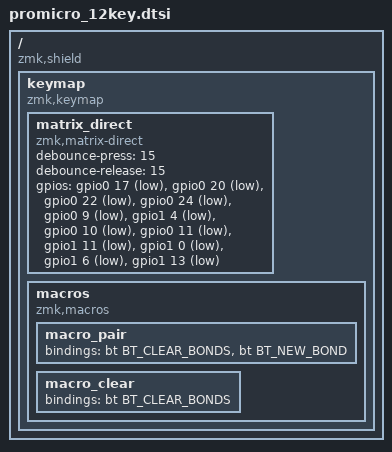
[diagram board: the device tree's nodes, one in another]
/ {
    compatible = "zmk,shield";

    keymap {
        compatible = "zmk,keymap";

        matrix_direct {
            compatible = "zmk,matrix-direct";
            //导电胶消抖15ms
            debounce-press = <15>;
            debounce-release = <15>;

            gpios =
                <&gpio0 17 GPIO_ACTIVE_LOW>,  // W
                <&gpio0 20 GPIO_ACTIVE_LOW>,  // A
                <&gpio0 22 GPIO_ACTIVE_LOW>,  // S
                <&gpio0 24 GPIO_ACTIVE_LOW>,  // D
                <&gpio0 9  GPIO_ACTIVE_LOW>,  // SPACE
                <&gpio1 4  GPIO_ACTIVE_LOW>,  // F
                <&gpio0 10 GPIO_ACTIVE_LOW>,  // E
                <&gpio0 11 GPIO_ACTIVE_LOW>,  // UP
                <&gpio1 11 GPIO_ACTIVE_LOW>,  // DOWN
                <&gpio1 0  GPIO_ACTIVE_LOW>,  // R
                <&gpio1 6  GPIO_ACTIVE_LOW>,  // LALT
                <&gpio1 13 GPIO_ACTIVE_LOW>;  // TAB
        };

        macros {
            compatible = "zmk,macros";
            // Tab+W+S：蓝牙配对
            macro_pair: macro_pair {
                bindings = <&bt BT_CLEAR_BONDS>, <&bt BT_NEW_BOND>;
            };
            // Tab+A+D：清除全部配对
            macro_clear: macro_clear {
                bindings = <&bt BT_CLEAR_BONDS>;
            };
        };
    };
};
